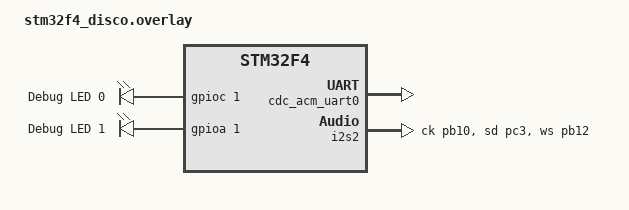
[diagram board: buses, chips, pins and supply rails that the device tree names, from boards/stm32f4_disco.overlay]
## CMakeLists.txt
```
cmake_minimum_required(VERSION 3.20.0)

#set(ZEPHYR_EXTRA_MODULES "${CMAKE_SOURCE_DIR}/../modules/....")
find_package(Zephyr REQUIRED HINTS $ENV{ZEPHYR_BASE})
project(audio_card_2)

target_sources(app
    PRIVATE
        src/main.c
        src/blink.c
        src/usb.c
        src/mic.c
        src/signal_buffer.c
        src/board_cli.c
        #src/cic.c
        #src/mic_filter.c
        src/pdm_to_pcm/cic.c
        src/pdm_to_pcm/decimator.c
        src/pdm_to_pcm/mic_filter.c
)

target_include_directories(app
    PRIVATE
        ./src
        ./src/pdm_to_pcm
)
```

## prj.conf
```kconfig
CONFIG_BOOT_BANNER=y

CONFIG_NET_BUF=y

CONFIG_USB_DEVICE_STACK=y
CONFIG_USB_DEVICE_PRODUCT="Zephyr USB console sample"
CONFIG_USB_DEVICE_PID=0x0004
CONFIG_USB_DEVICE_INITIALIZE_AT_BOOT=n
#CONFIG_USB_DEVICE_AUDIO=y

CONFIG_SERIAL=y
CONFIG_CONSOLE=y
CONFIG_UART_CONSOLE=y
CONFIG_UART_LINE_CTRL=y

CONFIG_SHELL=y
CONFIG_SHELL_BACKEND_SERIAL=y

CONFIG_PRINTK=y
CONFIG_GPIO=y

CONFIG_LOG=y
CONFIG_USB_DRIVER_LOG_LEVEL_ERR=y
CONFIG_USB_DEVICE_LOG_LEVEL_ERR=y

#
#CONFIG_AUDIO=y
#CONFIG_AUDIO_CODEC=y
#CONFIG_AUDIO_CODEC_CS43L22=y
#CONFIG_SAMPLE_FREQ=8000
#
#CONFIG_I2S=y
#CONFIG_I2S_STM32=y
#
#CONFIG_NET_BUF=y

CONFIG_DEBUG=y
CONFIG_LED=y
CONFIG_LED_GPIO=y

CONFIG_HEAP_MEM_POOL_SIZE=16384

#CONFIG_CMSIS=y
CONFIG_CMSIS_DSP=y
CONFIG_CMSIS_DSP_FILTERING=y
```

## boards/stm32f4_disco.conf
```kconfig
CONFIG_I2S=y
CONFIG_I2S_STM32=y
CONFIG_DMA=y
```

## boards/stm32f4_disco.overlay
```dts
/ {
	aliases {
		ledg = &green_led_4;
		ledo = &orange_led_3;
		ledr = &red_led_5;
		ledb = &blue_led_6;
	};

	chosen {
		zephyr,console = &cdc_acm_uart0;
		zephyr,shell-uart = &cdc_acm_uart0;
	};

	debug_leds {
		compatible = "gpio-leds";
		debug_led_0: dled_0 {
			gpios = < &gpioc 1 GPIO_ACTIVE_HIGH>;
			label = "Debug LED 0";
		};
		debug_led_1: dled_1 {
			gpios = < &gpioa 1 GPIO_ACTIVE_HIGH>;
			label = "Debug LED 1";
		};
	};
};

&zephyr_udc0 {
	cdc_acm_uart0: cdc_acm_uart0 {
		compatible = "zephyr,cdc-acm-uart";
	};
};

&i2s2 {
    status = "okay";
    pinctrl-0 = <&i2s2_ck_pb10 &i2s2_sd_pc3 &i2s2_ws_pb12>;
    pinctrl-names = "default";
};

/* In order to work "semi-correct" configure the frequency of the i2s
 * PLL that is the same as freuqnecy of the PCLK1Frequ - due to the bug in the
 * i2s_ll_stm32.
 */
&plli2s {
	mul-n = < 84 >;
	div-r = < 2 >;
};

&i2s2_sd_pc3 {
	slew-rate = "high-speed";
};
```

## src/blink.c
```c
#include <stdio.h>
#include <zephyr/device.h>
#include <zephyr/kernel.h>
#include <zephyr/devicetree.h>
#include <zephyr/logging/log.h>
#include <zephyr/drivers/gpio.h>

LOG_MODULE_REGISTER(blink, LOG_LEVEL_INF);
#define STACKSIZE 1024
#define PRIORITY 7
#define SLEEP_TIME_MS 100

enum leds {
    LED_GREEN = 0,
    LED_ORANGE,
    LED_RED,
    LED_BLUE,
    LED_LAST
};

static const struct gpio_dt_spec leds[LED_LAST] = {
	[LED_GREEN] = GPIO_DT_SPEC_GET(DT_ALIAS(ledg), gpios),
	[LED_ORANGE] = GPIO_DT_SPEC_GET(DT_ALIAS(ledo), gpios),
	[LED_RED] = GPIO_DT_SPEC_GET(DT_ALIAS(ledr), gpios),
	[LED_BLUE] = GPIO_DT_SPEC_GET(DT_ALIAS(ledb), gpios)
};

int init(void) 
{
    int rv = 0;

    for (size_t i = 0; i < LED_LAST; i++) {
        if (!gpio_is_ready_dt(&leds[i])) {       // Fix readiness check
            LOG_ERR("Led (index %d) not ready.", i);
            return -ENODEV;
        }

        rv = gpio_pin_configure_dt(&leds[i], GPIO_OUTPUT_ACTIVE);
        if (rv < 0) {
            LOG_ERR("Cannot configure led (index %d).", i);
            return rv;
        }
    }

    return rv;
}

static void thread(void *p1, void *p2, void *p3)
{
    int ret = init();
    if (ret < 0) {
        return;
    }

	int current_led_indx = 0;
	while(1) {
		ret = gpio_pin_toggle_dt(&leds[current_led_indx]);
		if (ret < 0) {
			LOG_ERR("Cannot toggle LED.");
			return;
		}
		current_led_indx = (current_led_indx + 1) % LED_LAST;
		k_msleep(SLEEP_TIME_MS);
	}
}

K_THREAD_DEFINE(blink_thread_id, STACKSIZE, thread, NULL, NULL, NULL,
		PRIORITY, 0, 0);
```

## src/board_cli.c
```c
#include <zephyr/kernel.h>
#include <zephyr/shell/shell.h>

/* ============================= */
/*  Subcommand handlers           */
/* ============================= */

static int cmd_board_clocks(const struct shell *sh, size_t argc, char **argv)
{
    shell_print(sh, "Clock information:");
    shell_print(sh, "\tSysClockFreq = %" PRIu32 " Hz", HAL_RCC_GetSysClockFreq());
    shell_print(sh, "\tHCLKFreq = %" PRIu32 " Hz", HAL_RCC_GetHCLKFreq());
    shell_print(sh, "\tPCLK1Freq = %" PRIu32 " Hz", HAL_RCC_GetPCLK1Freq());
    shell_print(sh, "\tPCLK2Freq = %" PRIu32 " Hz", HAL_RCC_GetPCLK2Freq());

    return 0;
}


SHELL_STATIC_SUBCMD_SET_CREATE(sub_board_cmds,
    SHELL_CMD(clocks, NULL, "Show clock configuration", cmd_board_clocks),
    SHELL_SUBCMD_SET_END /* Must be last */
);


SHELL_CMD_REGISTER(board, &sub_board_cmds,
                   "Board-related commands", NULL);
```

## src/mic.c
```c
#include <zephyr/kernel.h>
#include <zephyr/device.h>
#include <zephyr/drivers/i2s.h>
//#include <zephyr/audio/dmic_sw_filter.h>
#include <zephyr/sys/printk.h>
#include <zephyr/drivers/led.h>

#include <zephyr/devicetree.h>
#include <zephyr/drivers/gpio.h>

#include "signal_buffer.h"
#include "mic_filter.h"


#define BLOCK_SIZE 32
#define NUM_BLOCKS 4

#define STACKSIZE 1024
#define PRIORITY 7
#define SLEEP_TIME_MS 100


#define DEBUG_LED_0 DT_NODELABEL(debug_led_0)
#define DEBUG_LED_1 DT_NODELABEL(debug_led_1)

const struct gpio_dt_spec debug_led = GPIO_DT_SPEC_GET(DEBUG_LED_0, gpios);
const struct gpio_dt_spec debug_led_1 = GPIO_DT_SPEC_GET(DEBUG_LED_1, gpios);

K_MEM_SLAB_DEFINE_STATIC(rx_slab, BLOCK_SIZE, NUM_BLOCKS, 4);



static void thread(void *p1, void *p2, void *p3)
{
    const struct device *i2s_dev = DEVICE_DT_GET(DT_NODELABEL(i2s2));


    if (!device_is_ready(i2s_dev)) {
        printk("I2S device not ready\n");
        return;
    }

    gpio_pin_configure_dt(&debug_led, GPIO_OUTPUT_ACTIVE);
    gpio_pin_configure_dt(&debug_led_1, GPIO_OUTPUT_ACTIVE);
    

    // --- Configure I2S RX ---
    struct i2s_config i2s_cfg = {
        .word_size = 16, // dummy for PDM
        .channels = 1, // mono PDM
        .format = (I2S_FMT_DATA_FORMAT_RIGHT_JUSTIFIED | I2S_FMT_BIT_CLK_INV),
        //.format = (I2S_FMT_DATA_FORMAT_RIGHT_JUSTIFIED),
        .frame_clk_freq = 4*16000, // PDM clock
        .block_size = BLOCK_SIZE,
        .mem_slab = &rx_slab,
        .timeout = 2000,
        .options = (I2S_OPT_BIT_CLK_MASTER | I2S_OPT_FRAME_CLK_MASTER),
    };


    int rv = i2s_configure(i2s_dev, I2S_DIR_RX, &i2s_cfg);
    if (0 != rv) {
        printk("I2S configuration failed.");
        return;
    }

    rv = i2s_trigger(i2s_dev, I2S_DIR_RX, I2S_TRIGGER_START);
    if (0 != rv) {
        printk("I2S trigger failed.");
        return;
    }

    mic_filter_init();

    printk("Start I2S loop");
    int32_t output_prev = 0;
    // --- Main loop ---
    while (1) {
        uint16_t *pdm_block;
        size_t size = BLOCK_SIZE;

#if 0
        int ret = i2s_read(i2s_dev, (void*)&pdm_block, &size);
        if (ret == 0) {
            size = (size >> 2);
            int32_t output = 0;
            for (size_t i = 0; i < size; i++)
            {
                uint32_t sample = pdm_block[i];
                uint32_t intermediate_count = 0;
                for (size_t b = 0; b < 32; b++)
                {
                    intermediate_count += (sample & 0x1);
                    sample = sample >> 1;
                }

                int32_t inc = intermediate_count;
                int32_t dec = (32 - intermediate_count) * (-1);

                //output += ((inc + dec) << 7);
                output += (inc + dec);
            }

            //int32_t comb = output - output_prev;
            //output_prev = output;

            //int32_t pcm_sample = comb >> 8;

            push_to_signal_buffer(output);
            gpio_pin_toggle_dt(&debug_led);

            k_mem_slab_free(&rx_slab, pdm_block);
        }
#else
        int ret = i2s_read(i2s_dev, (void*)&pdm_block, &size);
        if (ret == 0) {
            size = (size >> 1);
            gpio_pin_set_dt(&debug_led_1, 1);
            for (size_t i = 0; i < size; i++)
            {
                uint16_t sample = pdm_block[i];
#if 0
                sample = ((sample & 0xFF00) >> 8) | ((sample & 0x00FF) << 8);
                for (size_t b = 0; b < (sizeof(sample) * 8); b++)
                {
                    int32_t is_new_sample_available = mic_filter_push(sample & 0x1);
                    if (0 != is_new_sample_available)
                    {
                        push_to_signal_buffer(mic_filter_get_last_output());
                    }
                    sample = sample >> 1;
                }
#else
                for (int32_t b = (sizeof(sample) * 8 - 1); b >= 0; b--)
                {
                    int32_t is_new_sample_available = mic_filter_push((sample >> b) & 0x1);
                    if (0 != is_new_sample_available)
                    {
                        push_to_signal_buffer(mic_filter_get_last_output());
                    }
                }
#endif
            }
            gpio_pin_set_dt(&debug_led_1, 0);

            gpio_pin_toggle_dt(&debug_led);

            k_mem_slab_free(&rx_slab, pdm_block);
        }
#endif
    }
}

K_THREAD_DEFINE(mic_thread_id, STACKSIZE, thread, NULL, NULL, NULL,
		PRIORITY, 0, 0);
```

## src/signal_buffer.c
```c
#include <stdint.h>

#include <zephyr/kernel.h>
#include <zephyr/logging/log.h>

LOG_MODULE_REGISTER(signal_buffer, LOG_LEVEL_INF);

#define AUDIO_SAMPLES_SIZE      32768
#define STACKSIZE 1024
#define PRIORITY 7
#define SLEEP_TIME_MS 10

static int16_t audio_samples[AUDIO_SAMPLES_SIZE] = {0}; 
static uint32_t audio_samples_indx = 0;

void push_to_signal_buffer(int16_t sample)
{
    audio_samples[audio_samples_indx] = sample;
    audio_samples_indx = (audio_samples_indx + 1) & ((1 << 15) - 1);
}

static void thread(void *p1, void *p2, void *p3)
{
    
    for(;;)
    {
        audio_samples[audio_samples_indx % AUDIO_SAMPLES_SIZE] = (audio_samples_indx);
        audio_samples_indx++;
        k_msleep(SLEEP_TIME_MS);
    }
}

//K_THREAD_DEFINE(signal_buffer_thread_id, STACKSIZE, thread, NULL, NULL, NULL,
//		PRIORITY, 0, 0);
```

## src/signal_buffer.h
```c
#ifndef _SIGNAL_BUFFER_H_
#define _SIGNAL_BUFFER_H_

#include <stdint.h>

void push_to_signal_buffer(int16_t sample);

#endif
```
